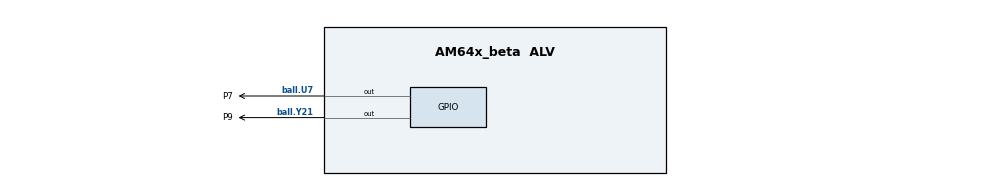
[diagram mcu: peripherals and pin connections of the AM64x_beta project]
/**
 * @cliArgs --device "AM64x_beta" --package "ALV" --part "Default" --context "r5fss0-1" --product "MCU_PLUS_SDK@07.03.01"
 * @versions {"tool":"1.9.0+2015","templates":null}
 */

/**
 * Import the modules used in this configuration.
 */
const gpio       = scripting.addModule("/drivers/gpio/gpio", {}, false);
const gpio1      = gpio.addInstance();
const gpio2      = gpio.addInstance();
const ipc        = scripting.addModule("/drivers/ipc/ipc");
const debug_log  = scripting.addModule("/kernel/dpl/debug_log");
const mpu_armv7  = scripting.addModule("/kernel/dpl/mpu_armv7", {}, false);
const mpu_armv71 = mpu_armv7.addInstance();
const mpu_armv72 = mpu_armv7.addInstance();
const mpu_armv73 = mpu_armv7.addInstance();
const mpu_armv74 = mpu_armv7.addInstance();
const mpu_armv75 = mpu_armv7.addInstance();
const mpu_armv76 = mpu_armv7.addInstance();
const mpu_armv77 = mpu_armv7.addInstance();

/**
 * Write custom configuration values to the imported modules.
 */
gpio1.pinDir               = "OUTPUT";
gpio1.$name                = "P7";
gpio1.GPIO.gpioPin.$assign = "ball.U7";

gpio2.$name                = "P9";
gpio2.pinDir               = "OUTPUT";
gpio2.GPIO.gpioPin.$assign = "ball.Y21";

ipc.m4fss0_0 = "NONE";

debug_log.enableCssLog       = false;
debug_log.enableSharedMemLog = true;
debug_log.enableUartLog      = true;
debug_log.uartLog.$name      = "CONFIG_UART0";

mpu_armv71.$name             = "CONFIG_MPU_REGION0";
mpu_armv71.size              = 31;
mpu_armv71.attributes        = "Device";
mpu_armv71.accessPermissions = "Supervisor RD+WR, User RD";
mpu_armv71.allowExecute      = false;

mpu_armv72.$name             = "CONFIG_MPU_REGION1";
mpu_armv72.size              = 15;
mpu_armv72.accessPermissions = "Supervisor RD+WR, User RD";

mpu_armv73.$name             = "CONFIG_MPU_REGION2";
mpu_armv73.baseAddr          = 0x41010000;
mpu_armv73.size              = 15;
mpu_armv73.accessPermissions = "Supervisor RD+WR, User RD";

mpu_armv74.$name             = "CONFIG_MPU_REGION3";
mpu_armv74.baseAddr          = 0x70000000;
mpu_armv74.size              = 21;
mpu_armv74.accessPermissions = "Supervisor RD+WR, User RD";

mpu_armv75.$name        = "CONFIG_MPU_REGION4";
mpu_armv75.attributes   = "Device";
mpu_armv75.allowExecute = false;
mpu_armv75.size         = 16;
mpu_armv75.baseAddr     = 0x701D0000;

mpu_armv76.$name             = "CONFIG_MPU_REGION5";
mpu_armv76.baseAddr          = 0x60000000;
mpu_armv76.size              = 28;
mpu_armv76.accessPermissions = "Supervisor RD, User RD";

mpu_armv77.$name    = "CONFIG_MPU_REGION6";
mpu_armv77.baseAddr = 0x80000000;
mpu_armv77.size     = 31;

/**
 * Pinmux solution for unlocked pins/peripherals. This ensures that minor changes to the automatic solver in a future
 * version of the tool will not impact the pinmux you originally saw.  These lines can be completely deleted in order to
 * re-solve from scratch.
 */
gpio1.GPIO.$suggestSolution                 = "GPIO0";
gpio2.GPIO.$suggestSolution                 = "GPIO0";
debug_log.uartLog.UART.$suggestSolution     = "USART2";
debug_log.uartLog.UART.RXD.$suggestSolution = "ball.K18";
debug_log.uartLog.UART.TXD.$suggestSolution = "ball.K19";
